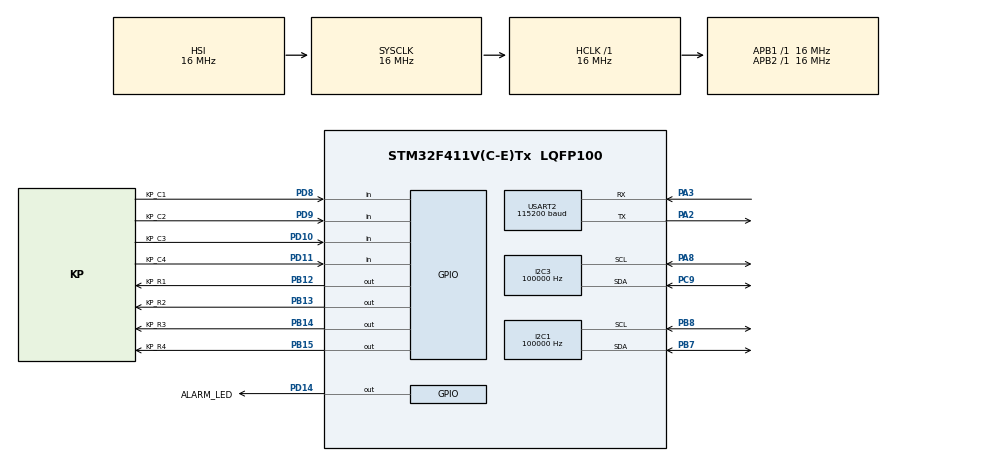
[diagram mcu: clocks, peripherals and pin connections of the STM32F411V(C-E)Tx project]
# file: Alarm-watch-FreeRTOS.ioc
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FREERTOS.Tasks01=defaultTask,24,128,StartDefaultTask,Default,NULL,Dynamic,NULL,NULL
FREERTOS.configUSE_NEWLIB_REENTRANT=1
I2C1.AddressingMode=I2C_ADDRESSINGMODE_7BIT
I2C1.ClockSpeed=100000
I2C1.DualAddressMode=I2C_DUALADDRESS_DISABLE
I2C1.GeneralCallMode=I2C_GENERALCALL_DISABLE
I2C1.I2C_Mode=I2C_Standard
I2C1.NoStretchMode=I2C_NOSTRETCH_DISABLE
I2C1.OwnAddress=0
I2C3.AddressingMode=I2C_ADDRESSINGMODE_7BIT
I2C3.ClockSpeed=100000
I2C3.DualAddressMode=I2C_DUALADDRESS_DISABLE
I2C3.GeneralCallMode=I2C_GENERALCALL_DISABLE
I2C3.I2C_Mode=I2C_Standard
I2C3.NoStretchMode=I2C_NOSTRETCH_DISABLE
I2C3.OwnAddress=0
Mcu.Family=STM32F4
Mcu.Name=STM32F411V(C-E)Tx
Mcu.Package=LQFP100
NVIC.PriorityGroup=NVIC_PRIORITYGROUP_4
NVIC.TIM5_IRQn=true\:15\:0\:false\:false\:true\:false\:false\:true\:true
NVIC.TimeBase=TIM5_IRQn
NVIC.TimeBaseIP=TIM5
PA13.Mode=Serial_Wire
PA13.Signal=SYS_JTMS-SWDIO
PA14.Mode=Serial_Wire
PA14.Signal=SYS_JTCK-SWCLK
PA2.Mode=Asynchronous
PA2.Signal=USART2_TX
PA3.Mode=Asynchronous
PA3.Signal=USART2_RX
PA8.Mode=I2C
PA8.Signal=I2C3_SCL
PB12.GPIO_Label=KP_R1
PB12.GPIO_Speed=GPIO_SPEED_FREQ_LOW
PB12.PinState=GPIO_PIN_SET
PB12.Signal=GPIO_Output
PB13.GPIO_Label=KP_R2
PB13.PinState=GPIO_PIN_SET
PB13.Signal=GPIO_Output
PB14.GPIO_Label=KP_R3
PB14.PinState=GPIO_PIN_SET
PB14.Signal=GPIO_Output
PB15.GPIO_Label=KP_R4
PB15.PinState=GPIO_PIN_SET
PB15.Signal=GPIO_Output
PB7.Mode=I2C
PB7.Signal=I2C1_SDA
PB8.Mode=I2C
PB8.Signal=I2C1_SCL
PC9.Mode=I2C
PC9.Signal=I2C3_SDA
PD10.GPIO_Label=KP_C3
PD10.GPIO_PuPd=GPIO_PULLUP
PD10.Signal=GPIO_Input
PD11.GPIO_Label=KP_C4
PD11.GPIO_PuPd=GPIO_PULLUP
PD11.Signal=GPIO_Input
PD14.GPIO_Label=ALARM_LED
PD14.Signal=GPIO_Output
PD8.GPIO_Label=KP_C1
PD8.GPIO_PuPd=GPIO_PULLUP
PD8.Signal=GPIO_Input
PD9.GPIO_Label=KP_C2
PD9.GPIO_PuPd=GPIO_PULLUP
PD9.Signal=GPIO_Input
ProjectManager.HeapSize=0x200
ProjectManager.StackSize=0x400
ProjectManager.TargetToolchain=STM32CubeIDE
RCC.AHBFreq_Value=16000000
RCC.APB1Freq_Value=16000000
RCC.APB2Freq_Value=16000000
RCC.CortexFreq_Value=16000000
RCC.HSE_VALUE=25000000
RCC.HSI_VALUE=16000000
RCC.LSE_VALUE=32768
RCC.SYSCLKFreq_VALUE=16000000
RCC.VCOOutputFreq_Value=192000000
USART2.BaudRate=115200
USART2.Mode=MODE_TX_RX
USART2.OverSampling=UART_OVERSAMPLING_16
USART2.Parity=PARITY_NONE
USART2.StopBits=STOPBITS_1
USART2.VirtualMode=VM_ASYNC
USART2.WordLength=WORDLENGTH_8B
VP_FREERTOS_VS_CMSIS_V2.Mode=CMSIS_V2
VP_SYS_VS_tim5.Mode=TIM5
board=custom

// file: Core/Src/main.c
/* USER CODE BEGIN Header */
/**
  ******************************************************************************
  * @file           : main.c
  * @brief          : Main program body
  ******************************************************************************
  * @attention
  *
  * Copyright (c) 2026 STMicroelectronics.
  * All rights reserved.
  *
  * This software is licensed under terms that can be found in the LICENSE file
  * in the root directory of this software component.
  * If no LICENSE file comes with this software, it is provided AS-IS.
  *
  ******************************************************************************
  */
/* USER CODE END Header */
#include "main.h"
#include "cmsis_os.h"

/* USER CODE BEGIN Includes */
#include "app_tasks.h"

/* USER CODE END Includes */

I2C_HandleTypeDef hi2c1;
I2C_HandleTypeDef hi2c3;

UART_HandleTypeDef huart2;

/* Definitions for defaultTask */
osThreadId_t defaultTaskHandle;
const osThreadAttr_t defaultTask_attributes = {
  .name = "defaultTask",
  .stack_size = 128 * 4,
  .priority = (osPriority_t) osPriorityNormal,
};

void SystemClock_Config(void);
static void MX_GPIO_Init(void);
static void MX_I2C3_Init(void);
static void MX_I2C1_Init(void);
static void MX_USART2_UART_Init(void);
void StartDefaultTask(void *argument);

int main(void)
{

  /* MCU Configuration--------------------------------------------------------*/

  /* Reset of all peripherals, Initializes the Flash interface and the Systick. */
  HAL_Init();

  /* Configure the system clock */
  SystemClock_Config();

  /* Initialize all configured peripherals */
  MX_GPIO_Init();
  MX_I2C3_Init();
  MX_I2C1_Init();
  MX_USART2_UART_Init();

  /* Init scheduler */
  osKernelInitialize();

  /* Create the thread(s) */
  /* creation of defaultTask */
  defaultTaskHandle = osThreadNew(StartDefaultTask, NULL, &defaultTask_attributes);

  /* USER CODE BEGIN RTOS_THREADS */
  /* add threads, ... */
  AppTasks_Init();

  /* USER CODE END RTOS_THREADS */

  /* Start scheduler */
  osKernelStart();

  /* We should never get here as control is now taken by the scheduler */

  /* Infinite loop */
  while (1)
  {

  }
}

void SystemClock_Config(void)
{
  RCC_OscInitTypeDef RCC_OscInitStruct = {0};
  RCC_ClkInitTypeDef RCC_ClkInitStruct = {0};

  /** Configure the main internal regulator output voltage
  */
  __HAL_RCC_PWR_CLK_ENABLE();
  __HAL_PWR_VOLTAGESCALING_CONFIG(PWR_REGULATOR_VOLTAGE_SCALE1);

  /** Initializes the RCC Oscillators according to the specified parameters
  * in the RCC_OscInitTypeDef structure.
  */
  RCC_OscInitStruct.OscillatorType = RCC_OSCILLATORTYPE_HSI;
  RCC_OscInitStruct.HSIState = RCC_HSI_ON;
  RCC_OscInitStruct.HSICalibrationValue = RCC_HSICALIBRATION_DEFAULT;
  RCC_OscInitStruct.PLL.PLLState = RCC_PLL_NONE;
  if (HAL_RCC_OscConfig(&RCC_OscInitStruct) != HAL_OK)
  {
    Error_Handler();
  }

  /** Initializes the CPU, AHB and APB buses clocks
  */
  RCC_ClkInitStruct.ClockType = RCC_CLOCKTYPE_HCLK|RCC_CLOCKTYPE_SYSCLK
                              |RCC_CLOCKTYPE_PCLK1|RCC_CLOCKTYPE_PCLK2;
  RCC_ClkInitStruct.SYSCLKSource = RCC_SYSCLKSOURCE_HSI;
  RCC_ClkInitStruct.AHBCLKDivider = RCC_SYSCLK_DIV1;
  RCC_ClkInitStruct.APB1CLKDivider = RCC_HCLK_DIV1;
  RCC_ClkInitStruct.APB2CLKDivider = RCC_HCLK_DIV1;

  if (HAL_RCC_ClockConfig(&RCC_ClkInitStruct, FLASH_LATENCY_0) != HAL_OK)
  {
    Error_Handler();
  }
}

static void MX_I2C1_Init(void)
{

  hi2c1.Instance = I2C1;
  hi2c1.Init.ClockSpeed = 100000;
  hi2c1.Init.DutyCycle = I2C_DUTYCYCLE_2;
  hi2c1.Init.OwnAddress1 = 0;
  hi2c1.Init.AddressingMode = I2C_ADDRESSINGMODE_7BIT;
  hi2c1.Init.DualAddressMode = I2C_DUALADDRESS_DISABLE;
  hi2c1.Init.OwnAddress2 = 0;
  hi2c1.Init.GeneralCallMode = I2C_GENERALCALL_DISABLE;
  hi2c1.Init.NoStretchMode = I2C_NOSTRETCH_DISABLE;
  if (HAL_I2C_Init(&hi2c1) != HAL_OK)
  {
    Error_Handler();
  }

}

static void MX_I2C3_Init(void)
{

  hi2c3.Instance = I2C3;
  hi2c3.Init.ClockSpeed = 100000;
  hi2c3.Init.DutyCycle = I2C_DUTYCYCLE_2;
  hi2c3.Init.OwnAddress1 = 0;
  hi2c3.Init.AddressingMode = I2C_ADDRESSINGMODE_7BIT;
  hi2c3.Init.DualAddressMode = I2C_DUALADDRESS_DISABLE;
  hi2c3.Init.OwnAddress2 = 0;
  hi2c3.Init.GeneralCallMode = I2C_GENERALCALL_DISABLE;
  hi2c3.Init.NoStretchMode = I2C_NOSTRETCH_DISABLE;
  if (HAL_I2C_Init(&hi2c3) != HAL_OK)
  {
    Error_Handler();
  }

}

static void MX_USART2_UART_Init(void)
{

  huart2.Instance = USART2;
  huart2.Init.BaudRate = 115200;
  huart2.Init.WordLength = UART_WORDLENGTH_8B;
  huart2.Init.StopBits = UART_STOPBITS_1;
  huart2.Init.Parity = UART_PARITY_NONE;
  huart2.Init.Mode = UART_MODE_TX_RX;
  huart2.Init.HwFlowCtl = UART_HWCONTROL_NONE;
  huart2.Init.OverSampling = UART_OVERSAMPLING_16;
  if (HAL_UART_Init(&huart2) != HAL_OK)
  {
    Error_Handler();
  }

}

static void MX_GPIO_Init(void)
{
  GPIO_InitTypeDef GPIO_InitStruct = {0};

  /* GPIO Ports Clock Enable */
  __HAL_RCC_GPIOA_CLK_ENABLE();
  __HAL_RCC_GPIOB_CLK_ENABLE();
  __HAL_RCC_GPIOD_CLK_ENABLE();
  __HAL_RCC_GPIOC_CLK_ENABLE();

  /*Configure GPIO pin Output Level */
  HAL_GPIO_WritePin(GPIOB, KP_R1_Pin|KP_R2_Pin|KP_R3_Pin|KP_R4_Pin, GPIO_PIN_SET);

  /*Configure GPIO pin Output Level */
  HAL_GPIO_WritePin(ALARM_LED_GPIO_Port, ALARM_LED_Pin, GPIO_PIN_RESET);

  /*Configure GPIO pins : KP_R1_Pin KP_R2_Pin KP_R3_Pin KP_R4_Pin */
  GPIO_InitStruct.Pin = KP_R1_Pin|KP_R2_Pin|KP_R3_Pin|KP_R4_Pin;
  GPIO_InitStruct.Mode = GPIO_MODE_OUTPUT_PP;
  GPIO_InitStruct.Pull = GPIO_NOPULL;
  GPIO_InitStruct.Speed = GPIO_SPEED_FREQ_LOW;
  HAL_GPIO_Init(GPIOB, &GPIO_InitStruct);

  /*Configure GPIO pins : KP_C1_Pin KP_C2_Pin KP_C3_Pin KP_C4_Pin */
  GPIO_InitStruct.Pin = KP_C1_Pin|KP_C2_Pin|KP_C3_Pin|KP_C4_Pin;
  GPIO_InitStruct.Mode = GPIO_MODE_INPUT;
  GPIO_InitStruct.Pull = GPIO_PULLUP;
  HAL_GPIO_Init(GPIOD, &GPIO_InitStruct);

  /*Configure GPIO pin : ALARM_LED_Pin */
  GPIO_InitStruct.Pin = ALARM_LED_Pin;
  GPIO_InitStruct.Mode = GPIO_MODE_OUTPUT_PP;
  GPIO_InitStruct.Pull = GPIO_NOPULL;
  GPIO_InitStruct.Speed = GPIO_SPEED_FREQ_LOW;
  HAL_GPIO_Init(ALARM_LED_GPIO_Port, &GPIO_InitStruct);

}

void StartDefaultTask(void *argument)
{
  for(;;)
  {
    osDelay(1);
  }
}

void HAL_TIM_PeriodElapsedCallback(TIM_HandleTypeDef *htim)
{
  if (htim->Instance == TIM5)
  {
    HAL_IncTick();
  }
}

void Error_Handler(void)
{
  __disable_irq();
  while (1)
  {
  }
}
